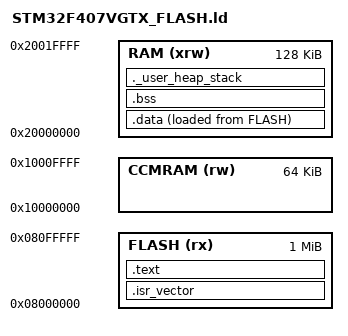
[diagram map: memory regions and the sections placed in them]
/* STM32F407VGTX Linker Script - FIXED VERSION */
ENTRY(Reset_Handler)

/* Highest address of the user mode stack */
_estack = 0x20020000;    /* 128K RAM end */
_Min_Heap_Size = 0x1000 ;  /* required amount of heap  */
_Min_Stack_Size = 0x400 ; /* required amount of stack */

/* Memories definition */
MEMORY
{
  FLASH (rx)  : ORIGIN = 0x08000000, LENGTH = 1024K
  RAM (xrw)   : ORIGIN = 0x20000000, LENGTH = 128K
  CCMRAM (rw) : ORIGIN = 0x10000000, LENGTH = 64K
}

/* Sections */
SECTIONS
{
  .isr_vector :
  {
    KEEP(*(.isr_vector))
  } >FLASH

  .text :
  {
    *(.text)
    *(.text*)
    *(.rodata)
    *(.rodata*)
    KEEP (*(.init))
    KEEP (*(.fini))
    _etext = .;
  } >FLASH

  /* Initialized data section */
  _sidata = LOADADDR(.data);

  .data : 
  {
    _sdata = .;
    *(.data)
    *(.data*)
    _edata = .;
  } >RAM AT> FLASH

  /* Uninitialized data section */
  .bss :
  {
    _sbss = .;
    __bss_start__ = _sbss;
    *(.bss)
    *(.bss*)
    *(COMMON)
    _ebss = .;
    __bss_end__ = _ebss;
  } >RAM

  /* Heap and stack */
  ._user_heap_stack :
  {
    . = ALIGN(8);
    PROVIDE(end = .);
    . = . + _Min_Heap_Size;
    . = . + _Min_Stack_Size;
    . = ALIGN(8);
  } >RAM
}
